# STM32G474 register map
File version: 2.9
CPU: CM4 r0p1, little endian, MPU, FPU, 4 interrupt priority bits
Registers are 32-bit, read-write, reset 0x0 unless marked. A register's access mark holds for its fields unless they carry their own. Offsets are from the block's base; [hi:lo] are bit positions.

## RNG — Random number generator
Base 0x50060800
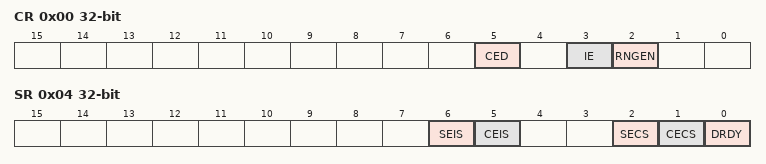
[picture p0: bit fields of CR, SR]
0x00 CR — control register
  [5] CED — Clock error detection
    0=Enabled (Clock error detection is enabled); 1=Disabled (Clock error detection is disabled)
  [3] IE — Interrupt enable
    0=Disabled (RNG interrupt is disabled); 1=Enabled (RNG interrupt is enabled)
  [2] RNGEN — Random number generator enable
    0=Disabled (Random number generator is disabled); 1=Enabled (Random number generator is enabled)
0x04 SR access per field — status register
  [6] SEIS rw write-0-clears — Seed error interrupt status
    on write: 0=Clear flag | on read: 0=No faulty sequence detected; 1=Fault (At least one faulty sequence has been detected. See **SECS** bit description for details. An interrupt is pending if IE = 1 in the RNG_CR register.)
  [5] CEIS rw write-0-clears — Clock error interrupt status
    on write: 0=Clear flag | on read: 0=Correct (The RNG clock is correct); 1=Slow (The RNG has been detected too slow An interrupt is pending if IE = 1 in the RNG_CR register)
  [2] SECS ro — Seed error current status
    0=No faulty sequence has currently been detected. If the SEIS bit is set, this means that a faulty sequence was detected and the situation has been recovered.; 1=Fault (At least one faulty sequence has been detected - see ref manual for details)
  [1] CECS ro — Clock error current status
    0=Correct (The RNG clock is correct. If the CEIS bit is set, this means that a slow clock was detected and the situation has been recovered.); 1=Slow (The RNG clock is too slow)
  [0] DRDY ro — Data ready
    0=Invalid (The RNG_DR register is not yet valid, no random data is available); 1=Valid (The RNG_DR register contains valid random data. Once the RNG_DR register has been read, this bit returns to 0 until a new random value is generated.)
0x08 DR ro — data register
  [31:0] RNDATA — Random data

## TIM6 — Basic-timers
Base 0x40001000
Same registers: TIM7 0x40001400
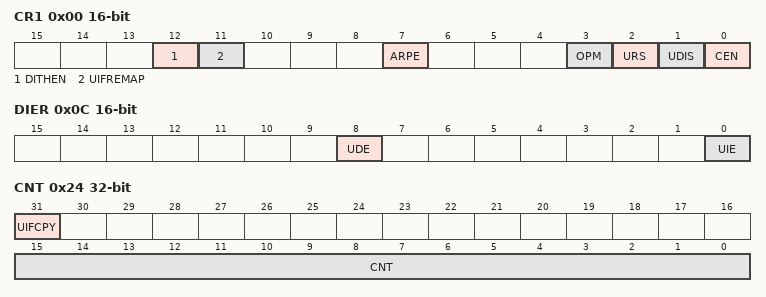
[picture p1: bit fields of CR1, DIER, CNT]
0x00 CR1 16-bit — TIM6 control register 1
  [12] DITHEN — Dithering enable
    0=Disabled (Dithering disabled); 1=Enabled (Dithering enabled)
  [11] UIFREMAP — UIF status bit remapping
    0=Disabled (No remapping. UIF status bit is not copied to TIMx_CNT register bit 31); 1=Enabled (Remapping enabled. UIF status bit is copied to TIMx_CNT register bit 31)
  [7] ARPE — Auto-reload preload enable
    0=Disabled (TIMx_APRR register is not buffered); 1=Enabled (TIMx_APRR register is buffered)
  [3] OPM — One-pulse mode
    0=Disabled (Counter is not stopped at update event); 1=Enabled (Counter stops counting at the next update event (clearing the CEN bit))
  [2] URS — Update request source
    0=AnyEvent (Any of counter overflow/underflow, setting UG, or update through slave mode, generates an update interrupt or DMA request); 1=CounterOnly (Only counter overflow/underflow generates an update interrupt or DMA request)
  [1] UDIS — Update disable
    0=Enabled (Update event enabled); 1=Disabled (Update event disabled)
  [0] CEN — Counter enable
    0=Disabled (Counter disabled); 1=Enabled (Counter enabled)
0x04 CR2 16-bit — TIM6 control register 2
  [6:4] MMS — Master mode selection
    0=Reset (Use UG bit from TIMx_EGR register); 1=Enable (Use CNT bit from TIMx_CEN register); 2=Update (Use the update event)
0x0C DIER 16-bit — TIM6 DMA/Interrupt enable register
  [8] UDE — Update DMA request enable
    0=Disabled (Update DMA request disabled); 1=Enabled (Update DMA request enabled)
  [0] UIE — Update interrupt enable
    0=Disabled (Update interrupt disabled); 1=Enabled (Update interrupt enabled)
0x10 SR 16-bit — TIM6 status register
  [0] UIF write-0-clears — Update interrupt flag
    on read: 0=NoUpdateOccurred; 1=UpdatePending (Update interrupt pending) | on write: 0=Clear flag
0x14 EGR 16-bit wo — TIM6 event generation register
  [0] UG — Update generation
    1=Update (Re-initializes the timer counter and generates an update of the registers.)
0x24 CNT — TIM6 counter
  [31] UIFCPY ro — UIF copy
    0=NoUpdateOccurred; 1=UpdatePending (Update interrupt pending)
  [15:0] CNT — Counter value
0x28 PSC 16-bit — TIM6 prescaler
  [15:0] PSC — Prescaler value
0x2C ARR reset 0xFFFF — TIM6 auto-reload register
  [19:0] ARR — Auto-reload value
